# RasbperryPi register map
File version: 1
Registers are 32-bit, read-write, reset 0x0 unless marked. A register's access mark holds for its fields unless they carry their own. Offsets are from the block's base; [hi:lo] are bit positions; {n}, {i} and the like mark numbered series.

## DMA — Derived from axi_dma_top.h
Base 0x7E007FE0
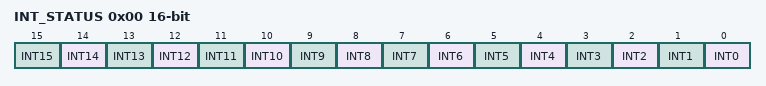
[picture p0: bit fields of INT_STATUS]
0x00 INT_STATUS 16-bit ro
  [n] INT{n} (n=0..15)
0x10 ENABLE 15-bit reset 0xFF
  [n] EN{n} (n=0..14)

## APERF0 — Derived from axi_performance0.h apb_id: 0x41584950
Base 0x7E009800
Same registers: APERF1 0x7EE08000
0x00 GEN_CTRL 2-bit
  [1] RESET, [0] ENABLE
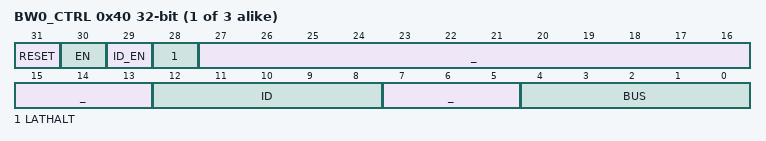
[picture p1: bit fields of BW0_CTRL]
{0x40+0x40*i} BW{i}_CTRL (i=0..2)
  [31] RESET, [30] EN, [29] ID_EN, [28] LATHALT, [27:13] _, [12:8] ID, [7:5] _, [4:0] BUS
{0x44+0x40*i} BW{i}_ATRANS ro (i=0..2)
  [31:0] data
{0x48+0x40*i} BW{i}_ATWAIT ro (i=0..2)
  [31:0] data
{0x4C+0x40*i} BW{i}_AMAX 24-bit ro (i=0..2)
  [23:0] data
{0x50+0x40*i} BW{i}_WTRANS ro (i=0..2)
  [31:0] data
{0x54+0x40*i} BW{i}_WTWAIT ro (i=0..2)
  [31:0] data
0x58 BW0_WMAX 24-bit ro
  [23:0] data
{0x5C+0x40*i} BW{i}_RTRANS ro (i=0..2)
  [31:0] data
{0x60+0x40*i} BW{i}_RTWAIT ro (i=0..2)
  [31:0] data
{0x64+0x40*i} BW{i}_RMAX 24-bit ro (i=0..2)
  [23:0] data
0x68 BW{i}_RPEND 8-bit ro (i=0..2)
  [7:0] data
0x98 BW1_WMAX 16-bit ro
  [15:0] data
0xD8 BW2_WMAX 28-bit ro
  [27:0] data

## CAM0 — Derived from cam0.h apb_id: 0x7563616D
Base 0x7E800000
Same registers: CAM1 0x7E801000, CAM1 0x7E801000
0x00 CAMCTL
  [31:0] data
0x00 CAMICTL
  [31:0] data
0x00 CAMDCS
  [31:0] data
0x00 CAMDBCTL
  [31:0] data
0x00 CAMMISC
  [31:0] data
0x04 CAMSTA
  [31:0] data
0x04 CAMISTA
  [31:0] data
0x04 CAMDBSA0
  [31:0] data
0x04 CAMIBSA1
  [31:0] data
0x08 CAMANA reset 0x77
  [31:0] data
0x08 CAMIDI0
  [31:0] data
0x08 CAMDBEA0
  [31:0] data
0x08 CAMIBEA1
  [31:0] data
0x0C CAMPRI
  [31:0] data
0x0C CAMIPIPE
  [31:0] data
0x0C CAMDBWP
  [31:0] data
0x0C CAMIDI1
  [31:0] data
0x10 CAMCLK reset 0x2
  [31:0] data
0x10 CAMIBSA0
  [31:0] data
0x10 CAMDBSA1
  [31:0] data
0x14 CAMCLT
  [31:0] data
0x14 CAMIBEA0
  [31:0] data
0x14 CAMDBEA1
  [31:0] data
{0x18+4i} CAMDAT{i} reset 0x2 (i=0..3)
  [31:0] data
0x18 CAMIBLS
  [31:0] data
0x1C CAMIBWP
  [31:0] data
0x20 CAMIHWIN
  [31:0] data
0x24 CAMIHSTA
  [31:0] data
0x28 CAMDLT
  [31:0] data
0x28 CAMIVWIN
  [31:0] data
0x2C CAMCMP0
  [31:0] data
0x2C CAMIVSTA
  [31:0] data
0x30 CAMCMP1
  [31:0] data
0x30 CAMICC
  [31:0] data
0x34 CAMCAP0
  [31:0] data
0x34 CAMICS
  [31:0] data
0x38 CAMCAP1
  [31:0] data
0x38 CAMIDC
  [31:0] data
0x3C CAMIDPO
  [31:0] data
0x40 CAMIDCA
  [31:0] data
0x44 CAMIDCD
  [31:0] data
0x48 CAMIDS
  [31:0] data
{0xF0+4i} CAMDBG{i} (i=0..3)
  [31:0] data
